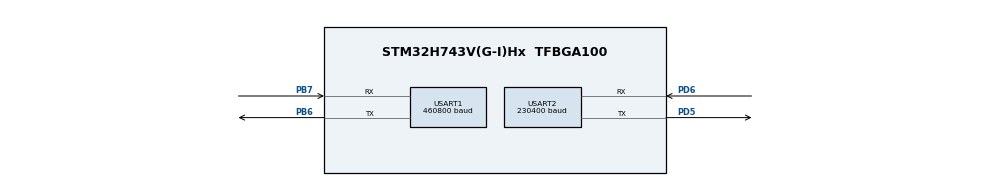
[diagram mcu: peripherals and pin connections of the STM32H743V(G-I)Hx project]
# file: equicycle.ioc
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CORTEX_M7.default_mode_Activation=1
Dma.Request0=USART2_RX
Dma.Request1=USART2_TX
Dma.USART2_RX.0.Direction=DMA_PERIPH_TO_MEMORY
Dma.USART2_RX.0.EventEnable=DISABLE
Dma.USART2_RX.0.FIFOMode=DMA_FIFOMODE_DISABLE
Dma.USART2_RX.0.Instance=DMA1_Stream0
Dma.USART2_RX.0.MemDataAlignment=DMA_MDATAALIGN_BYTE
Dma.USART2_RX.0.MemInc=DMA_MINC_ENABLE
Dma.USART2_RX.0.Mode=DMA_NORMAL
Dma.USART2_RX.0.PeriphDataAlignment=DMA_PDATAALIGN_BYTE
Dma.USART2_RX.0.PeriphInc=DMA_PINC_DISABLE
Dma.USART2_RX.0.Polarity=HAL_DMAMUX_REQ_GEN_RISING
Dma.USART2_RX.0.Priority=DMA_PRIORITY_LOW
Dma.USART2_RX.0.RequestNumber=1
Dma.USART2_RX.0.SignalID=NONE
Dma.USART2_RX.0.SyncEnable=DISABLE
Dma.USART2_RX.0.SyncPolarity=HAL_DMAMUX_SYNC_NO_EVENT
Dma.USART2_RX.0.SyncRequestNumber=1
Dma.USART2_RX.0.SyncSignalID=NONE
Dma.USART2_TX.1.Direction=DMA_MEMORY_TO_PERIPH
Dma.USART2_TX.1.EventEnable=DISABLE
Dma.USART2_TX.1.FIFOMode=DMA_FIFOMODE_DISABLE
Dma.USART2_TX.1.Instance=DMA1_Stream1
Dma.USART2_TX.1.MemDataAlignment=DMA_MDATAALIGN_BYTE
Dma.USART2_TX.1.MemInc=DMA_MINC_ENABLE
Dma.USART2_TX.1.Mode=DMA_NORMAL
Dma.USART2_TX.1.PeriphDataAlignment=DMA_PDATAALIGN_BYTE
Dma.USART2_TX.1.PeriphInc=DMA_PINC_DISABLE
Dma.USART2_TX.1.Polarity=HAL_DMAMUX_REQ_GEN_RISING
Dma.USART2_TX.1.Priority=DMA_PRIORITY_LOW
Dma.USART2_TX.1.RequestNumber=1
Dma.USART2_TX.1.SignalID=NONE
Dma.USART2_TX.1.SyncEnable=DISABLE
Dma.USART2_TX.1.SyncPolarity=HAL_DMAMUX_SYNC_NO_EVENT
Dma.USART2_TX.1.SyncRequestNumber=1
Dma.USART2_TX.1.SyncSignalID=NONE
Mcu.Family=STM32H7
Mcu.Name=STM32H743V(G-I)Hx
Mcu.Package=TFBGA100
NVIC.DMA1_Stream0_IRQn=true\:0\:0\:false\:false\:true\:false\:true\:true
NVIC.DMA1_Stream1_IRQn=true\:0\:0\:false\:false\:true\:false\:true\:true
NVIC.PriorityGroup=NVIC_PRIORITYGROUP_4
NVIC.USART1_IRQn=true\:0\:0\:false\:false\:true\:true\:true\:true
NVIC.USART2_IRQn=true\:0\:0\:false\:false\:true\:true\:true\:true
PA13\ (JTMS/SWDIO).Mode=Serial_Wire
PA13\ (JTMS/SWDIO).Signal=DEBUG_JTMS-SWDIO
PA14\ (JTCK/SWCLK).Mode=Serial_Wire
PA14\ (JTCK/SWCLK).Signal=DEBUG_JTCK-SWCLK
PB6.Mode=Asynchronous
PB6.Signal=USART1_TX
PB7.Mode=Asynchronous
PB7.Signal=USART1_RX
PD5.Mode=Asynchronous
PD5.Signal=USART2_TX
PD6.Mode=Asynchronous
PD6.Signal=USART2_RX
PH0-OSC_IN\ (PH0).Mode=HSE-External-Oscillator
PH0-OSC_IN\ (PH0).Signal=RCC_OSC_IN
PH1-OSC_OUT\ (PH1).Mode=HSE-External-Oscillator
PH1-OSC_OUT\ (PH1).Signal=RCC_OSC_OUT
ProjectManager.HeapSize=0x200
ProjectManager.StackSize=0x400
ProjectManager.TargetToolchain=CMake
RCC.ADCFreq_Value=129000000
RCC.APB1Freq_Value=100000000
RCC.APB2Freq_Value=100000000
RCC.APB3Freq_Value=100000000
RCC.APB4Freq_Value=100000000
RCC.CortexFreq_Value=400000000
RCC.D1PPRE=RCC_APB3_DIV2
RCC.D2PPRE1=RCC_APB1_DIV2
RCC.D2PPRE2=RCC_APB2_DIV2
RCC.D3PPRE=RCC_APB4_DIV2
RCC.DIVM1=4
RCC.DIVN1=50
RCC.HCLKFreq_Value=200000000
RCC.HPRE=RCC_HCLK_DIV2
RCC.PLL2FRACN=0
RCC.PLL3FRACN=0
RCC.PLLFRACN=0
RCC.SYSCLKFreq_VALUE=400000000
RCC.SYSCLKSource=RCC_SYSCLKSOURCE_PLLCLK
RCC.USBFreq_Value=400000000
USART1.BaudRate=460800
USART1.VirtualMode-Asynchronous=VM_ASYNC
USART2.BaudRate=230400
USART2.VirtualMode-Asynchronous=VM_ASYNC
board=custom

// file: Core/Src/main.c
/* USER CODE BEGIN Header */
/**
 ******************************************************************************
 * @file           : main.c
 * @brief          : Main program body
 ******************************************************************************
 * @attention
 *
 * Copyright (c) 2024 STMicroelectronics.
 * All rights reserved.
 *
 * This software is licensed under terms that can be found in the LICENSE file
 * in the root directory of this software component.
 * If no LICENSE file comes with this software, it is provided AS-IS.
 *
 ******************************************************************************
 */
/* USER CODE END Header */
#include "main.h"
#include "dma.h"
#include "usart.h"
#include "gpio.h"

void SystemClock_Config(void);
static void MPU_Config(void);

int main(void)
{

  /* MPU Configuration--------------------------------------------------------*/
  MPU_Config();

  /* MCU Configuration--------------------------------------------------------*/

  /* Reset of all peripherals, Initializes the Flash interface and the Systick. */
  HAL_Init();

  /* Configure the system clock */
  SystemClock_Config();

  /* Initialize all configured peripherals */
  MX_GPIO_Init();
  MX_DMA_Init();
  MX_USART2_UART_Init();
  MX_USART1_UART_Init();
  /* USER CODE BEGIN 2 */
  // test
  cpp_test_function();
  /* USER CODE END 2 */

  /* Infinite loop */
  while (1)
  {

  }
}

void SystemClock_Config(void)
{
  RCC_OscInitTypeDef RCC_OscInitStruct = {0};
  RCC_ClkInitTypeDef RCC_ClkInitStruct = {0};

  /** Supply configuration update enable
   */
  HAL_PWREx_ConfigSupply(PWR_LDO_SUPPLY);

  /** Configure the main internal regulator output voltage
   */
  __HAL_PWR_VOLTAGESCALING_CONFIG(PWR_REGULATOR_VOLTAGE_SCALE1);

  while (!__HAL_PWR_GET_FLAG(PWR_FLAG_VOSRDY))
  {
  }

  /** Initializes the RCC Oscillators according to the specified parameters
   * in the RCC_OscInitTypeDef structure.
   */
  RCC_OscInitStruct.OscillatorType = RCC_OSCILLATORTYPE_HSI;
  RCC_OscInitStruct.HSIState = RCC_HSI_DIV1;
  RCC_OscInitStruct.HSICalibrationValue = RCC_HSICALIBRATION_DEFAULT;
  RCC_OscInitStruct.PLL.PLLState = RCC_PLL_ON;
  RCC_OscInitStruct.PLL.PLLSource = RCC_PLLSOURCE_HSI;
  RCC_OscInitStruct.PLL.PLLM = 4;
  RCC_OscInitStruct.PLL.PLLN = 50;
  RCC_OscInitStruct.PLL.PLLP = 2;
  RCC_OscInitStruct.PLL.PLLQ = 2;
  RCC_OscInitStruct.PLL.PLLR = 2;
  RCC_OscInitStruct.PLL.PLLRGE = RCC_PLL1VCIRANGE_3;
  RCC_OscInitStruct.PLL.PLLVCOSEL = RCC_PLL1VCOWIDE;
  RCC_OscInitStruct.PLL.PLLFRACN = 0;
  if (HAL_RCC_OscConfig(&RCC_OscInitStruct) != HAL_OK)
  {
    Error_Handler();
  }

  /** Initializes the CPU, AHB and APB buses clocks
   */
  RCC_ClkInitStruct.ClockType = RCC_CLOCKTYPE_HCLK | RCC_CLOCKTYPE_SYSCLK | RCC_CLOCKTYPE_PCLK1 | RCC_CLOCKTYPE_PCLK2 | RCC_CLOCKTYPE_D3PCLK1 | RCC_CLOCKTYPE_D1PCLK1;
  RCC_ClkInitStruct.SYSCLKSource = RCC_SYSCLKSOURCE_PLLCLK;
  RCC_ClkInitStruct.SYSCLKDivider = RCC_SYSCLK_DIV1;
  RCC_ClkInitStruct.AHBCLKDivider = RCC_HCLK_DIV2;
  RCC_ClkInitStruct.APB3CLKDivider = RCC_APB3_DIV2;
  RCC_ClkInitStruct.APB1CLKDivider = RCC_APB1_DIV2;
  RCC_ClkInitStruct.APB2CLKDivider = RCC_APB2_DIV2;
  RCC_ClkInitStruct.APB4CLKDivider = RCC_APB4_DIV2;

  if (HAL_RCC_ClockConfig(&RCC_ClkInitStruct, FLASH_LATENCY_2) != HAL_OK)
  {
    Error_Handler();
  }
}

/* MPU Configuration */

void MPU_Config(void)
{
  MPU_Region_InitTypeDef MPU_InitStruct = {0};

  /* Disables the MPU */
  HAL_MPU_Disable();

  /** Initializes and configures the Region and the memory to be protected
   */
  MPU_InitStruct.Enable = MPU_REGION_ENABLE;
  MPU_InitStruct.Number = MPU_REGION_NUMBER0;
  MPU_InitStruct.BaseAddress = 0x0;
  MPU_InitStruct.Size = MPU_REGION_SIZE_4GB;
  MPU_InitStruct.SubRegionDisable = 0x87;
  MPU_InitStruct.TypeExtField = MPU_TEX_LEVEL0;
  MPU_InitStruct.AccessPermission = MPU_REGION_NO_ACCESS;
  MPU_InitStruct.DisableExec = MPU_INSTRUCTION_ACCESS_DISABLE;
  MPU_InitStruct.IsShareable = MPU_ACCESS_SHAREABLE;
  MPU_InitStruct.IsCacheable = MPU_ACCESS_NOT_CACHEABLE;
  MPU_InitStruct.IsBufferable = MPU_ACCESS_NOT_BUFFERABLE;

  HAL_MPU_ConfigRegion(&MPU_InitStruct);
  /* Enables the MPU */
  HAL_MPU_Enable(MPU_PRIVILEGED_DEFAULT);
}

void Error_Handler(void)
{
  __disable_irq();
  while (1)
  {
  }
}
